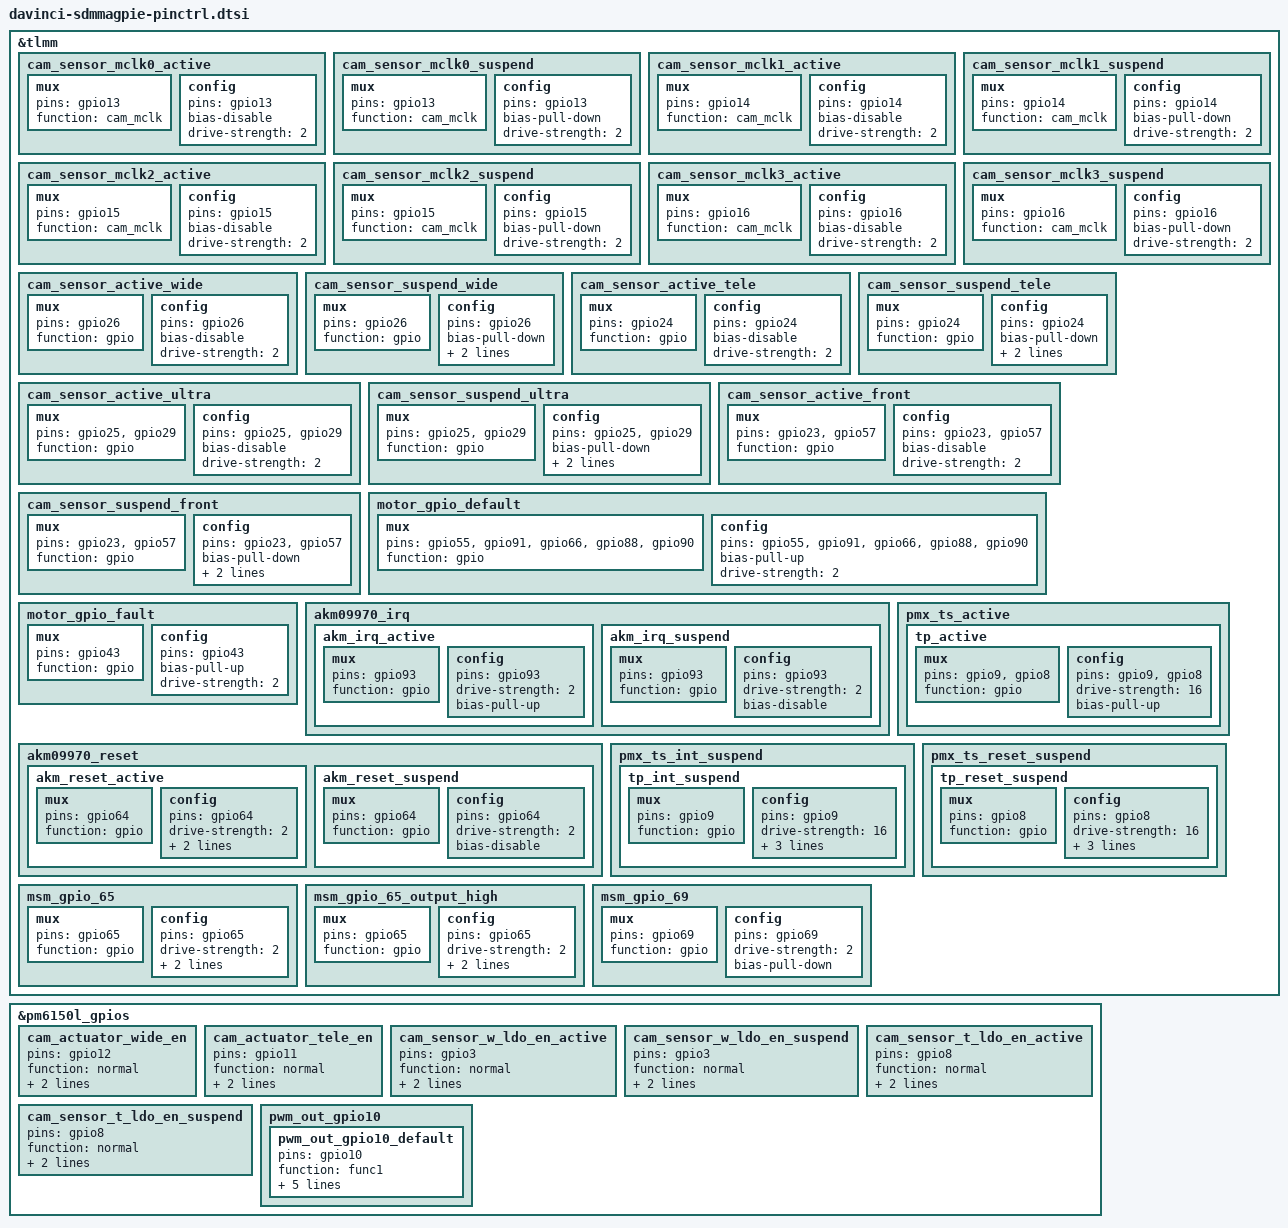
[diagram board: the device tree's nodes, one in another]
/*for F10 SM7150 pinctrl*/

&tlmm {

	cam_sensor_mclk0_active: cam_sensor_mclk0_active {
		/* MCLK0 */
		mux {
			pins = "gpio13";
			function = "cam_mclk";
		};

		config {
			pins = "gpio13";
			bias-disable; /* No PULL */
			drive-strength = <2>; /* 2 MA */
		};
	};

	cam_sensor_mclk0_suspend: cam_sensor_mclk0_suspend {
		/* MCLK0 */
		mux {
			pins = "gpio13";
			function = "cam_mclk";
		};

		config {
			pins = "gpio13";
			bias-pull-down; /* PULL DOWN */
			drive-strength = <2>; /* 2 MA */
		};
	};

	cam_sensor_mclk1_active: cam_sensor_mclk1_active {
		/* MCLK1 */
		mux {
			pins = "gpio14";
			function = "cam_mclk";
		};

		config {
			pins = "gpio14";
			bias-disable; /* No PULL */
			drive-strength = <2>; /* 2 MA */
		};
	};

	cam_sensor_mclk1_suspend: cam_sensor_mclk1_suspend {
		/* MCLK1 */
		mux {
			pins = "gpio14";
			function = "cam_mclk";
		};

		config {
			pins = "gpio14";
			bias-pull-down; /* PULL DOWN */
			drive-strength = <2>; /* 2 MA */
		};
	};

	cam_sensor_mclk2_active: cam_sensor_mclk2_active {
		/* MCLK2 */
		mux {
			pins = "gpio15";
			function = "cam_mclk";
		};

		config {
			pins = "gpio15";
			bias-disable; /* No PULL */
			drive-strength = <2>; /* 2 MA */
		};
	};

	cam_sensor_mclk2_suspend: cam_sensor_mclk2_suspend {
		/* MCLK2 */
		mux {
			pins = "gpio15";
			function = "cam_mclk";
		};

		config {
			pins = "gpio15";
			bias-pull-down; /* PULL DOWN */
			drive-strength = <2>; /* 2 MA */
		};
	};

	cam_sensor_mclk3_active: cam_sensor_mclk3_active {
		/* MCLK3 */
		mux {
			pins = "gpio16";
			function = "cam_mclk";
		};

		config {
			pins = "gpio16";
			bias-disable; /* No PULL */
			drive-strength = <2>; /* 2 MA */
		};
	};

	cam_sensor_mclk3_suspend: cam_sensor_mclk3_suspend {
		/* MCLK3 */
		mux {
			pins = "gpio16";
			function = "cam_mclk";
		};

		config {
			pins = "gpio16";
			bias-pull-down; /* PULL DOWN */
			drive-strength = <2>; /* 2 MA */
		};
	};


	cam_sensor_active_wide: cam_sensor_active_wide {
		/* WIDE RESET */
		mux {
			pins = "gpio26";
			function = "gpio";
		};

		config {
			pins = "gpio26";
			bias-disable; /* No PULL */
			drive-strength = <2>; /* 2 MA */
		};
	};

	cam_sensor_suspend_wide: cam_sensor_suspend_wide {
		/* WIDE RESET */
		mux {
			pins = "gpio26";
			function = "gpio";
		};

		config {
			pins = "gpio26";
			bias-pull-down; /* PULL DOWN */
			drive-strength = <2>; /* 2 MA */
			output-low;
		};
	};

	cam_sensor_active_tele: cam_sensor_active_tele {
		/* TELE RESET */
		mux {
			pins = "gpio24";
			function = "gpio";
		};

		config {
			pins = "gpio24";
			bias-disable; /* No PULL */
			drive-strength = <2>; /* 2 MA */
		};
	};

	cam_sensor_suspend_tele: cam_sensor_suspend_tele {
		/* TELE RESET */
		mux {
			pins = "gpio24";
			function = "gpio";
		};

		config {
			pins = "gpio24";
			bias-pull-down; /* PULL DOWN */
			drive-strength = <2>; /* 2 MA */
			output-low;
		};
	};

	cam_sensor_active_ultra: cam_sensor_active_ultra {
		/* ULTRA RESET DVDDEN */
		mux {
			pins = "gpio25", "gpio29";
			function = "gpio";
		};

		config {
			pins = "gpio25", "gpio29";
			bias-disable; /* No PULL */
			drive-strength = <2>; /* 2 MA */
		};
	};

	cam_sensor_suspend_ultra: cam_sensor_suspend_ultra {
		/* ULTRA RESET DVDDEN */
		mux {
			pins = "gpio25", "gpio29";
			function = "gpio";
		};

		config {
			pins = "gpio25", "gpio29";
			bias-pull-down; /* PULL DOWN */
			drive-strength = <2>; /* 2 MA */
			output-low;
		};
	};

	cam_sensor_active_front: cam_sensor_active_front {
		/* FRONT RESET DVDDEN */
		mux {
			pins = "gpio23", "gpio57";
			function = "gpio";
		};

		config {
			pins = "gpio23", "gpio57";
			bias-disable; /* No PULL */
			drive-strength = <2>; /* 2 MA */
		};
	};

	cam_sensor_suspend_front: cam_sensor_suspend_front {
		/* FRONT RESET DVDDEN */
		mux {
			pins = "gpio23", "gpio57";
			function = "gpio";
		};

		config {
			pins = "gpio23", "gpio57";
			bias-pull-down; /* PULL DOWN */
			drive-strength = <2>; /* 2 MA */
			output-low;
		};
	};

	motor_gpio_default: motor_gpio_default {
		mux {
			/* DIR, M0, M1, SLEEP, EN */
			pins = "gpio55", "gpio91", "gpio66", "gpio88", "gpio90";
			function = "gpio";
		};

		config {
			/* DIR, M0, M1, SLEEP, EN */
			pins = "gpio55", "gpio91", "gpio66", "gpio88", "gpio90";
			bias-pull-up; /* No PULL */
			drive-strength = <2>; /* 2 MA */
		};
	};

	motor_gpio_fault: motor_gpio_fault {
		mux {
			pins = "gpio43";
			function = "gpio";
		};

		config {
			pins = "gpio43";
			bias-pull-up; /* No PULL */
			drive-strength = <2>; /* 2 MA */
		};
	};


	akm09970_irq {
		akm_irq_active: akm_irq_active {
			mux {
				pins = "gpio93";
				function = "gpio";
			};

			config {
				pins = "gpio93";
				drive-strength = <2>; /* 2 MA */
				bias-pull-up; /* No PULL */
			};
		};

		akm_irq_suspend: akm_irq_suspend {
			mux {
				pins = "gpio93";
				function = "gpio";
			};

			config {
				pins = "gpio93";
				drive-strength = <2>; /* 2 MA */
				bias-disable;
			};
		};
	};

	akm09970_reset {
		akm_reset_active: akm_reset_active {
			mux {
				pins = "gpio64";
				function = "gpio";
			};

			config {
				pins = "gpio64";
				drive-strength = <2>; /* 2 MA */
				bias-pull-down; /* No PULL */
				output-low;
			};
		};

		akm_reset_suspend: akm_reset_suspend {
			mux {
				pins = "gpio64";
				function = "gpio";
			};

			config {
				pins = "gpio64";
				drive-strength = <2>; /* 2 MA */
				bias-disable;
			};
		};
	};

	/*touchpanel*/
	pmx_ts_active {
			tp_active: tp_active {
					mux {
						pins = "gpio9", "gpio8";
						function = "gpio";
					};
					config {
						pins = "gpio9", "gpio8";
						drive-strength = <16>;
						bias-pull-up;
					};
			};
	};

	pmx_ts_int_suspend {
			tp_int_suspend: tp_int_suspend {
				mux {
					pins = "gpio9";
					function = "gpio";
				};
				config {
					pins = "gpio9";
					drive-strength = <16>;
					input-enable;
					slew-rate = <0>;
					bias-pull-up = <00>;
				};
			};
	};

	pmx_ts_reset_suspend {
			tp_reset_suspend: tp_reset_suspend {
				mux {
					pins = "gpio8";
					function = "gpio";
				};
				config {
					pins = "gpio8";
					drive-strength = <16>;
					slew-rate = <1>;
					bias-disable;
					output-high;
				};
			};
	};
};

&pm6150l_gpios {

	cam_actuator_wide_en: cam_actuator_wide_en {
		pins = "gpio12";
		function = "normal";
		power-source = <1>; //to be confirmed
		output-low;
	};
	cam_actuator_tele_en: cam_actuator_tele_en {
		pins = "gpio11";
		function = "normal";
		power-source = <1>; //to be confirmed
		output-low;
	};

	cam_sensor_w_ldo_en_active: cam_sensor_w_ldo_en_active {
		pins = "gpio3";
		function = "normal";
		power-source = <0>;
		output-low; //ABNER
	};
	cam_sensor_w_ldo_en_suspend: cam_sensor_w_ldo_en_suspend {
		pins = "gpio3";
		function = "normal";
		power-source = <0>;
		output-low;
	};

	cam_sensor_t_ldo_en_active: cam_sensor_t_ldo_en_active {
		pins = "gpio8";
		function = "normal";
		power-source = <0>; //to be confirmed
		output-low; //ABNER
	};
	cam_sensor_t_ldo_en_suspend: cam_sensor_t_ldo_en_suspend {
		pins = "gpio8";
		function = "normal";
		power-source = <0>; //to be confirmed
		output-low;
	};

	pwm_out_gpio10 {
		pwm_out_gpio10_default: pwm_out_gpio10_default {
			pins = "gpio10";
			function = "func1";
			bias-disable;
			power-source = <1>;
			output-low;
			qcom,drive-strength = <3>;
			drive-push-pull;
		};
	};
};

&tlmm {
        /* GPIO_65 : FP_RESET_N */
        msm_gpio_65: msm_gpio_65 {
                mux {
                         pins = "gpio65";
                         function = "gpio";
                };

                config {
                        pins = "gpio65";
                        drive-strength = <2>;
                        bias-disable;
                        output-low;
                };
        };

        /* GPIO_65 : FP_RESET_N, state device active*/
        msm_gpio_65_output_high: msm_gpio_65_output_high {
                mux {
                        pins = "gpio65";
                        function = "gpio";
                };

                config {
                        pins = "gpio65";
                        drive-strength = <2>;
                        bias-disable;
                        output-high;
                };
        };

        /* GPIO_69 : FP_INT_N */
        msm_gpio_69: msm_gpio_69 {
                mux {
                        pins = "gpio69";
                        function = "gpio";
                };

                config {
                        pins = "gpio69";
                        drive-strength = <2>;
                        bias-pull-down;
                };
    };

};

